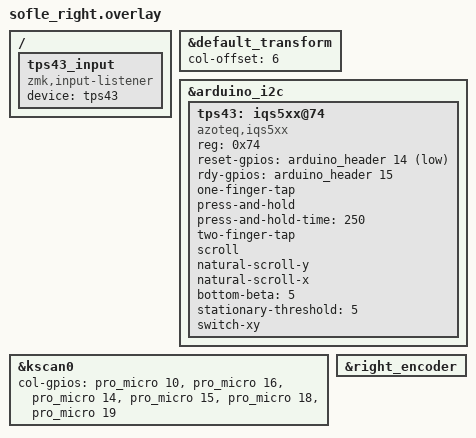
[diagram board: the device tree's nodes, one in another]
/*
 * Copyright (c) 2020 Ryan Cross
 *
 * SPDX-License-Identifier: MIT
 */

#include "sofle.dtsi"

&default_transform {
    col-offset = <6>;
};

/ {
    tps43_input: tps43_input {
        compatible = "zmk,input-listener";
        device = <&tps43>;
    };
};

&arduino_i2c {
    status = "okay";
    tps43: iqs5xx@74 {
        status = "okay";
        compatible = "azoteq,iqs5xx";
        reg = <0x74>;

        reset-gpios = <&arduino_header 14 GPIO_ACTIVE_LOW>;
        rdy-gpios = <&arduino_header 15 GPIO_ACTIVE_HIGH>;

        /*
         * Potentially non-exhaustive list of configuration options.
         * See: dts/bindings/input/azoteq,iqs5xx-common.yaml for a full list.
         */
        one-finger-tap;
        press-and-hold;
        press-and-hold-time = <250>;
        two-finger-tap;

        scroll;
        natural-scroll-y;
        natural-scroll-x;

        bottom-beta = <5>;
        stationary-threshold = <5>;

        switch-xy;
    };
};

&kscan0 {
    col-gpios
        = <&pro_micro 10 GPIO_ACTIVE_HIGH>
        , <&pro_micro 16 GPIO_ACTIVE_HIGH>
        , <&pro_micro 14 GPIO_ACTIVE_HIGH>
        , <&pro_micro 15 GPIO_ACTIVE_HIGH>
        , <&pro_micro 18 GPIO_ACTIVE_HIGH>
        , <&pro_micro 19 GPIO_ACTIVE_HIGH>
        ;
};

&right_encoder {
    status = "okay";
};
